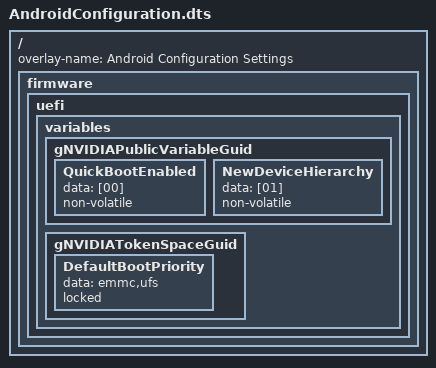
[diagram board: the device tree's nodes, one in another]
/** @file
*
*  SPDX-FileCopyrightText: Copyright (c) 2022-2024 NVIDIA CORPORATION & AFFILIATES. All rights reserved.
*
*  SPDX-License-Identifier: BSD-2-Clause-Patent
*
**/

/dts-v1/;
/plugin/;

/ {
	overlay-name = "Android Configuration Settings";

	fragment@0 {
		target-path = "/";
		board_config {
			sw-modules = "uefi";
		};

		__overlay__ {
			firmware {
				uefi {
					variables {
						gNVIDIAPublicVariableGuid {
							QuickBootEnabled {
								data = [00];
								non-volatile;
							};
							NewDeviceHierarchy {
								data = [01];
								non-volatile;
							};
						};

						gNVIDIATokenSpaceGuid {
							DefaultBootPriority {
								data = "emmc,ufs";
								locked;
							};
						};
					};
				};
			};
		};
	};
};
